VERSION ""

NS_ :

BS_:

BU_: XXX

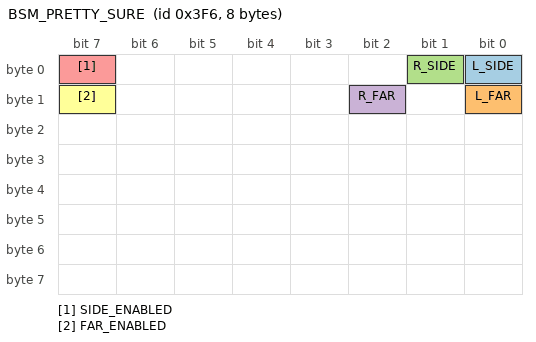
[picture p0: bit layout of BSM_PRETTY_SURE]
BO_ 1014 BSM_PRETTY_SURE: 8 XXX
 SG_ L_SIDE : 0|1@0+ (1,0) [0|1] "" XXX
 SG_ L_FAR : 8|1@0+ (1,0) [0|1] "" XXX
 SG_ R_SIDE : 1|1@0+ (1,0) [0|1] "" XXX
 SG_ R_FAR : 10|1@0+ (1,0) [0|1] "" XXX
 SG_ SIDE_ENABLED : 7|1@0+ (1,0) [0|1] "" XXX
 SG_ FAR_ENABLED : 15|1@0+ (1,0) [0|1] "" XXX
